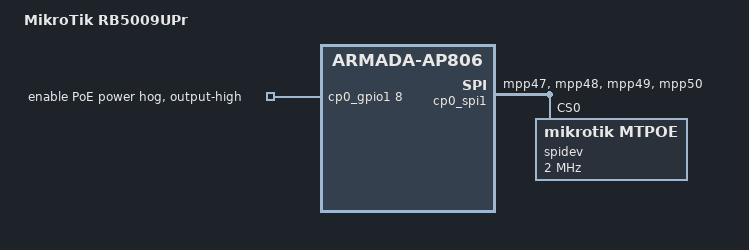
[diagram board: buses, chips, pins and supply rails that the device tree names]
// SPDX-License-Identifier: GPL-2.0-or-later OR MIT

/dts-v1/;

#include "armada-7040-rb5009.dtsi"

/ {
	model = "MikroTik RB5009UPr";
	compatible = "mikrotik,rb5009upr", "marvell,armada7040",
		     "marvell,armada-ap806-quad", "marvell,armada-ap806";
};

&cp0_gpio1 {
	enable-poe-power {
		gpio-hog;
		gpios = <8 GPIO_ACTIVE_HIGH>;
		output-high;
		line-name = "enable PoE power";
	};
};

&cp0_pinctrl {
	cp0_spi1_pins: cp0-spi1-pins {
		marvell,pins = "mpp47", "mpp48", "mpp49", "mpp50";
		marvell,function = "spi1";
	};
};

&cp0_spi1 {
	status = "okay";

	pinctrl-0 = <&cp0_spi1_pins>;
	pinctrl-names = "default";

	spidev@0 {
		compatible = "mikrotik,mtpoe";
		reg = <0>;
		spi-max-frequency = <2000000>;
	};
};
